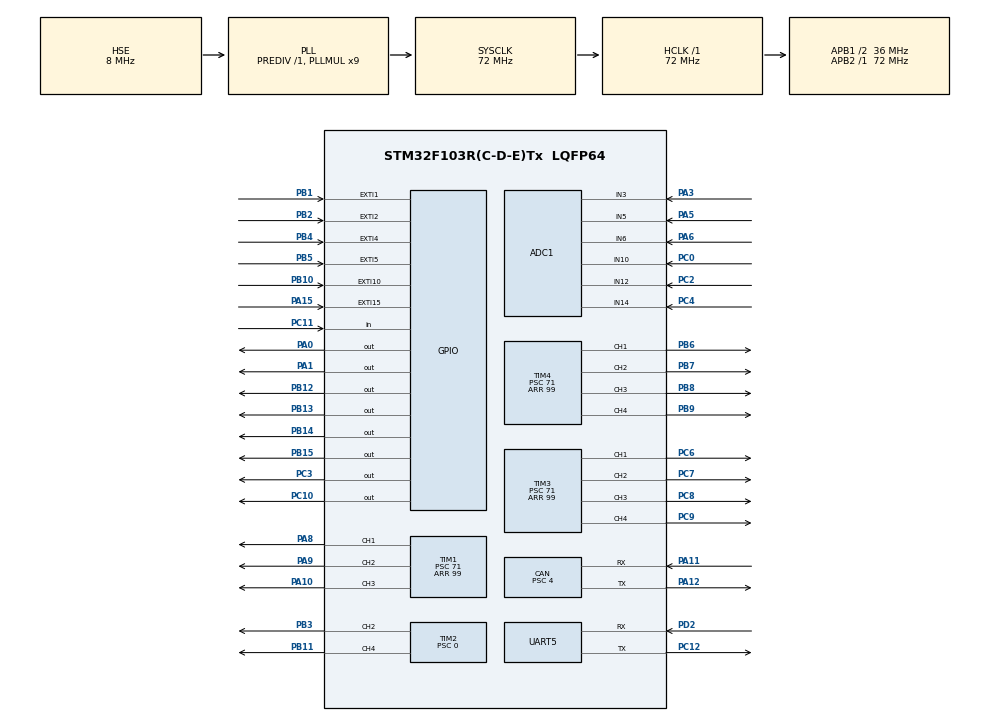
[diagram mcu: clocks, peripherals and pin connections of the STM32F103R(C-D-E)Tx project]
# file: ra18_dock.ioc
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ADC1.Channel-0\#ChannelRegularConversion=ADC_CHANNEL_3
ADC1.Channel-1\#ChannelRegularConversion=ADC_CHANNEL_5
ADC1.Channel-2\#ChannelRegularConversion=ADC_CHANNEL_6
ADC1.Channel-3\#ChannelRegularConversion=ADC_CHANNEL_10
ADC1.Channel-4\#ChannelRegularConversion=ADC_CHANNEL_12
ADC1.Channel-5\#ChannelRegularConversion=ADC_CHANNEL_14
ADC1.ContinuousConvMode=ENABLE
ADC1.DiscontinuousConvMode=DISABLE
ADC1.EnableInjectedConversion=DISABLE
ADC1.InjNumberOfConversion=4
ADC1.NbrOfConversion=6
ADC1.NbrOfConversionFlag=1
ADC1.Rank-0\#ChannelRegularConversion=1
ADC1.Rank-1\#ChannelRegularConversion=2
ADC1.Rank-2\#ChannelRegularConversion=3
ADC1.Rank-3\#ChannelRegularConversion=4
ADC1.Rank-4\#ChannelRegularConversion=5
ADC1.Rank-5\#ChannelRegularConversion=6
ADC1.SamplingTime-0\#ChannelRegularConversion=ADC_SAMPLETIME_1CYCLE_5
ADC1.SamplingTime-1\#ChannelRegularConversion=ADC_SAMPLETIME_1CYCLE_5
ADC1.SamplingTime-2\#ChannelRegularConversion=ADC_SAMPLETIME_1CYCLE_5
ADC1.SamplingTime-3\#ChannelRegularConversion=ADC_SAMPLETIME_1CYCLE_5
ADC1.SamplingTime-4\#ChannelRegularConversion=ADC_SAMPLETIME_1CYCLE_5
ADC1.SamplingTime-5\#ChannelRegularConversion=ADC_SAMPLETIME_1CYCLE_5
ADC1.master=1
CAN.ABOM=ENABLE
CAN.AWUM=ENABLE
CAN.BS1=CAN_BS1_5TQ
CAN.BS2=CAN_BS2_3TQ
CAN.CalculateBaudRate=1000000
CAN.CalculateTimeBit=1000
CAN.CalculateTimeQuantum=111.11111111111111
CAN.Prescaler=4
CAN.SJW=CAN_SJW_2TQ
Dma.ADC1.0.Direction=DMA_PERIPH_TO_MEMORY
Dma.ADC1.0.Instance=DMA1_Channel1
Dma.ADC1.0.MemDataAlignment=DMA_MDATAALIGN_HALFWORD
Dma.ADC1.0.MemInc=DMA_MINC_ENABLE
Dma.ADC1.0.Mode=DMA_NORMAL
Dma.ADC1.0.PeriphDataAlignment=DMA_PDATAALIGN_HALFWORD
Dma.ADC1.0.PeriphInc=DMA_PINC_DISABLE
Dma.ADC1.0.Priority=DMA_PRIORITY_LOW
Dma.Request0=ADC1
Mcu.Family=STM32F1
Mcu.Name=STM32F103R(C-D-E)Tx
Mcu.Package=LQFP64
NVIC.CAN1_RX1_IRQn=true\:3\:0\:true\:false\:true\:true\:true\:true
NVIC.CAN1_SCE_IRQn=true\:3\:0\:true\:false\:true\:true\:true\:true
NVIC.DMA1_Channel1_IRQn=true\:0\:0\:false\:false\:true\:false\:true\:true
NVIC.PriorityGroup=NVIC_PRIORITYGROUP_4
NVIC.TIM5_IRQn=true\:14\:0\:true\:false\:true\:true\:true\:true
NVIC.UART5_IRQn=true\:2\:0\:true\:false\:true\:true\:true\:true
NVIC.USB_LP_CAN1_RX0_IRQn=true\:4\:0\:true\:false\:true\:true\:true\:true
PA0-WKUP.Signal=GPIO_Output
PA1.Signal=GPIO_Output
PA10.Signal=S_TIM1_CH3
PA10.Stacked=true
PA11.Mode=CAN_Activate
PA11.Signal=CAN_RX
PA11.Stacked=true
PA12.Mode=CAN_Activate
PA12.Signal=CAN_TX
PA12.Stacked=true
PA13.Mode=Serial_Wire
PA13.Signal=SYS_JTMS-SWDIO
PA14.Mode=Serial_Wire
PA14.Signal=SYS_JTCK-SWCLK
PA15.Signal=GPXTI15
PA15.Stacked=true
PA2.Signal=ADCx_IN2
PA2.Stacked=true
PA3.Signal=ADCx_IN3
PA3.Stacked=true
PA4.Signal=ADCx_IN4
PA4.Stacked=true
PA5.Signal=ADCx_IN5
PA5.Stacked=true
PA6.Signal=ADCx_IN6
PA6.Stacked=true
PA7.Signal=ADCx_IN7
PA7.Stacked=true
PA8.Signal=S_TIM1_CH1
PA8.Stacked=true
PA9.Signal=S_TIM1_CH2
PA9.Stacked=true
PB0.Signal=ADCx_IN8
PB0.Stacked=true
PB1.Signal=GPXTI1
PB1.Stacked=true
PB10.Signal=GPXTI10
PB10.Stacked=true
PB11.Signal=S_TIM2_CH4
PB11.Stacked=true
PB12.Signal=GPIO_Output
PB12.Stacked=true
PB13.Signal=GPIO_Output
PB13.Stacked=true
PB14.Signal=GPIO_Output
PB14.Stacked=true
PB15.Signal=GPIO_Output
PB15.Stacked=true
PB2.Signal=GPXTI2
PB2.Stacked=true
PB3.Signal=S_TIM2_CH2
PB4.Signal=GPXTI4
PB4.Stacked=true
PB5.Signal=GPXTI5
PB5.Stacked=true
PB6.Signal=S_TIM4_CH1
PB6.Stacked=true
PB7.Signal=S_TIM4_CH2
PB7.Stacked=true
PB8.Signal=S_TIM4_CH3
PB8.Stacked=true
PB9.Signal=S_TIM4_CH4
PB9.Stacked=true
PC0.Signal=ADCx_IN10
PC0.Stacked=true
PC1.Signal=ADCx_IN11
PC1.Stacked=true
PC10.Signal=SharedStack_PC10
PC10.Stacked=true
PC11.Signal=SharedStack_PC11
PC11.Stacked=true
PC12.Mode=Asynchronous
PC12.Signal=UART5_TX
PC12.Stacked=true
PC2.Signal=ADCx_IN12
PC2.Stacked=true
PC3.Signal=GPIO_Output
PC3.Stacked=true
PC4.Signal=ADCx_IN14
PC4.Stacked=true
PC5.Signal=ADCx_IN15
PC5.Stacked=true
PC6.Signal=S_TIM3_CH1
PC6.Stacked=true
PC7.Signal=S_TIM3_CH2
PC7.Stacked=true
PC8.Signal=S_TIM3_CH3
PC8.Stacked=true
PC9.Signal=S_TIM3_CH4
PC9.Stacked=true
PD0-OSC_IN.Mode=HSE-External-Oscillator
PD0-OSC_IN.Signal=RCC_OSC_IN
PD1-OSC_OUT.Mode=HSE-External-Oscillator
PD1-OSC_OUT.Signal=RCC_OSC_OUT
PD2.GPIO_PuPd=GPIO_PULLUP
PD2.Mode=Asynchronous
PD2.Signal=UART5_RX
PD2.Stacked=true
ProjectManager.HeapSize=0x200
ProjectManager.StackSize=0x400
ProjectManager.TargetToolchain=STM32CubeIDE
RCC.ADCPresc=RCC_ADCPCLK2_DIV6
RCC.AHBFreq_Value=72000000
RCC.APB1CLKDivider=RCC_HCLK_DIV2
RCC.APB1Freq_Value=36000000
RCC.APB1TimFreq_Value=72000000
RCC.APB2Freq_Value=72000000
RCC.APB2TimFreq_Value=72000000
RCC.HCLKFreq_Value=72000000
RCC.PLLMUL=RCC_PLL_MUL9
RCC.PLLSourceVirtual=RCC_PLLSOURCE_HSE
RCC.SYSCLKFreq_VALUE=72000000
RCC.SYSCLKSource=RCC_SYSCLKSOURCE_PLLCLK
RCC.USBFreq_Value=72000000
SH.ADCx_IN10.0=ADC1_IN10,IN10
SH.ADCx_IN11.0=ADC1_IN11
SH.ADCx_IN12.0=ADC1_IN12,IN12
SH.ADCx_IN14.0=ADC1_IN14,IN14
SH.ADCx_IN15.0=ADC1_IN15
SH.ADCx_IN2.0=ADC1_IN2
SH.ADCx_IN3.0=ADC1_IN3,IN3
SH.ADCx_IN4.0=ADC1_IN4
SH.ADCx_IN5.0=ADC1_IN5,IN5
SH.ADCx_IN6.0=ADC1_IN6,IN6
SH.ADCx_IN7.0=ADC1_IN7
SH.ADCx_IN8.0=ADC1_IN8
SH.S_TIM1_CH1.0=TIM1_CH1,PWM Generation1 CH1
SH.S_TIM1_CH2.0=TIM1_CH2,PWM Generation2 CH2
SH.S_TIM1_CH3.0=TIM1_CH3,PWM Generation3 CH3
SH.S_TIM2_CH2.0=TIM2_CH2,PWM Generation2 CH2
SH.S_TIM2_CH4.0=TIM2_CH4,PWM Generation4 CH4
SH.S_TIM3_CH1.0=TIM3_CH1,PWM Generation1 CH1
SH.S_TIM3_CH2.0=TIM3_CH2,PWM Generation2 CH2
SH.S_TIM3_CH3.0=TIM3_CH3,PWM Generation3 CH3
SH.S_TIM3_CH4.0=TIM3_CH4,PWM Generation4 CH4
SH.S_TIM4_CH1.0=TIM4_CH1,PWM Generation1 CH1
SH.S_TIM4_CH2.0=TIM4_CH2,PWM Generation2 CH2
SH.S_TIM4_CH3.0=TIM4_CH3,PWM Generation3 CH3
SH.S_TIM4_CH4.0=TIM4_CH4,PWM Generation4 CH4
SH.SharedStack_PC10.0=UART4_TX
SH.SharedStack_PC10.1=GPIO_Output
SH.SharedStack_PC11.0=UART4_RX
SH.SharedStack_PC11.1=GPIO_Input
TIM1.Channel-PWM\ Generation1\ CH1=TIM_CHANNEL_1
TIM1.Channel-PWM\ Generation2\ CH2=TIM_CHANNEL_2
TIM1.Channel-PWM\ Generation3\ CH3=TIM_CHANNEL_3
TIM1.Channel-PWM\ Generation4\ CH4=TIM_CHANNEL_4
TIM1.Period=99
TIM1.Prescaler=71
TIM2.Channel-PWM\ Generation2\ CH2=TIM_CHANNEL_2
TIM2.Channel-PWM\ Generation4\ CH4=TIM_CHANNEL_4
TIM2.Period=89
TIM2.Prescaler=0
TIM3.Channel-PWM\ Generation1\ CH1=TIM_CHANNEL_1
TIM3.Channel-PWM\ Generation2\ CH2=TIM_CHANNEL_2
TIM3.Channel-PWM\ Generation3\ CH3=TIM_CHANNEL_3
TIM3.Channel-PWM\ Generation4\ CH4=TIM_CHANNEL_4
TIM3.Period=99
TIM3.Prescaler=71
TIM4.Channel-PWM\ Generation1\ CH1=TIM_CHANNEL_1
TIM4.Channel-PWM\ Generation2\ CH2=TIM_CHANNEL_2
TIM4.Channel-PWM\ Generation3\ CH3=TIM_CHANNEL_3
TIM4.Channel-PWM\ Generation4\ CH4=TIM_CHANNEL_4
TIM4.Period=99
TIM4.Prescaler=71
TIM5.Channel-PWM\ Generation1\ CH1=TIM_CHANNEL_1
TIM5.Channel-PWM\ Generation2\ CH2=TIM_CHANNEL_2
TIM5.Period=49999
TIM5.Prescaler=71
UART5.VirtualMode=Asynchronous
VP_TIM1_VS_ClockSourceINT.Mode=Internal
VP_TIM2_VS_ClockSourceINT.Mode=Internal
VP_TIM3_VS_ClockSourceINT.Mode=Internal
VP_TIM4_VS_ClockSourceINT.Mode=Internal
VP_TIM5_VS_ClockSourceINT.Mode=Internal
board=custom

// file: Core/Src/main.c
/* USER CODE BEGIN Header */
/**
  ******************************************************************************
  * @file           : main.c
  * @brief          : Main program body
  ******************************************************************************
  * @attention
  *
  * Copyright (c) 2025 STMicroelectronics.
  * All rights reserved.
  *
  * This software is licensed under terms that can be found in the LICENSE file
  * in the root directory of this software component.
  * If no LICENSE file comes with this software, it is provided AS-IS.
  *
  ******************************************************************************
  */
/* USER CODE END Header */
#include "main.h"
#include "adc.h"
#include "can.h"
#include "dma.h"
#include "tim.h"
#include "usart.h"
#include "gpio.h"

void SystemClock_Config(void);
/* USER CODE BEGIN PFP */
void user_setup(void);
void user_loop(void);
/* USER CODE END PFP */

int main(void)
{

  /* MCU Configuration--------------------------------------------------------*/

  /* Reset of all peripherals, Initializes the Flash interface and the Systick. */
  HAL_Init();

  /* Configure the system clock */
  SystemClock_Config();

  /* Initialize all configured peripherals */
  MX_GPIO_Init();
  MX_DMA_Init();
  MX_ADC1_Init();
  MX_TIM1_Init();
  MX_TIM2_Init();
  MX_TIM3_Init();
  MX_TIM4_Init();
  MX_UART5_Init();
  MX_CAN_Init();
  MX_TIM5_Init();
  /* USER CODE BEGIN 2 */
  user_setup();
  /* USER CODE END 2 */

  /* Infinite loop */
  /* USER CODE BEGIN WHILE */
  while (1)
  {
	  user_loop();
    /* USER CODE END WHILE */

  }
}

void SystemClock_Config(void)
{
  RCC_OscInitTypeDef RCC_OscInitStruct = {0};
  RCC_ClkInitTypeDef RCC_ClkInitStruct = {0};
  RCC_PeriphCLKInitTypeDef PeriphClkInit = {0};

  /** Initializes the RCC Oscillators according to the specified parameters
  * in the RCC_OscInitTypeDef structure.
  */
  RCC_OscInitStruct.OscillatorType = RCC_OSCILLATORTYPE_HSE;
  RCC_OscInitStruct.HSEState = RCC_HSE_ON;
  RCC_OscInitStruct.HSEPredivValue = RCC_HSE_PREDIV_DIV1;
  RCC_OscInitStruct.HSIState = RCC_HSI_ON;
  RCC_OscInitStruct.PLL.PLLState = RCC_PLL_ON;
  RCC_OscInitStruct.PLL.PLLSource = RCC_PLLSOURCE_HSE;
  RCC_OscInitStruct.PLL.PLLMUL = RCC_PLL_MUL9;
  if (HAL_RCC_OscConfig(&RCC_OscInitStruct) != HAL_OK)
  {
    Error_Handler();
  }

  /** Initializes the CPU, AHB and APB buses clocks
  */
  RCC_ClkInitStruct.ClockType = RCC_CLOCKTYPE_HCLK|RCC_CLOCKTYPE_SYSCLK
                              |RCC_CLOCKTYPE_PCLK1|RCC_CLOCKTYPE_PCLK2;
  RCC_ClkInitStruct.SYSCLKSource = RCC_SYSCLKSOURCE_PLLCLK;
  RCC_ClkInitStruct.AHBCLKDivider = RCC_SYSCLK_DIV1;
  RCC_ClkInitStruct.APB1CLKDivider = RCC_HCLK_DIV2;
  RCC_ClkInitStruct.APB2CLKDivider = RCC_HCLK_DIV1;

  if (HAL_RCC_ClockConfig(&RCC_ClkInitStruct, FLASH_LATENCY_2) != HAL_OK)
  {
    Error_Handler();
  }
  PeriphClkInit.PeriphClockSelection = RCC_PERIPHCLK_ADC;
  PeriphClkInit.AdcClockSelection = RCC_ADCPCLK2_DIV6;
  if (HAL_RCCEx_PeriphCLKConfig(&PeriphClkInit) != HAL_OK)
  {
    Error_Handler();
  }
}

void Error_Handler(void)
{
  __disable_irq();
  while (1)
  {
  }
}
